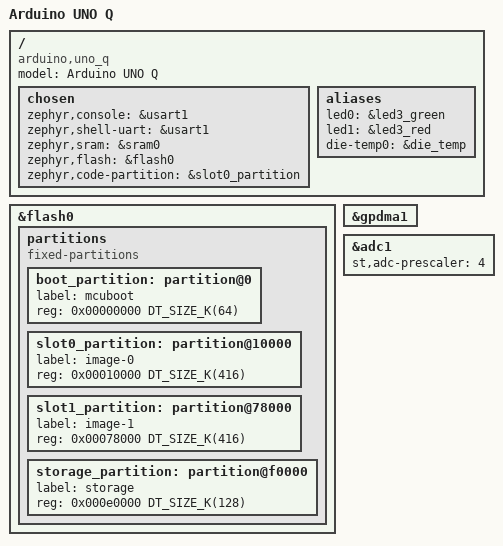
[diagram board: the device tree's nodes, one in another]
/*
 * Copyright (c) 2025 Arduino SA
 *
 * SPDX-License-Identifier: Apache-2.0
 */

/dts-v1/;
#include "arduino_uno_q-common.dtsi"
#include <zephyr/dt-bindings/memory-attr/memory-attr.h>
#include <zephyr/dt-bindings/memory-attr/memory-attr-arm.h>

/ {
	model = "Arduino UNO Q";
	compatible = "arduino,uno_q";

	chosen {
		zephyr,console = &usart1;
		zephyr,shell-uart = &usart1;
		zephyr,sram = &sram0;
		zephyr,flash = &flash0;
		zephyr,code-partition = &slot0_partition;
	};

	aliases {
		led0 = &led3_green;
		led1 = &led3_red;
		die-temp0 = &die_temp;
	};
};

&flash0 {
	partitions {
		compatible = "fixed-partitions";
		#address-cells = <1>;
		#size-cells = <1>;

		/*
		 * Following flash partition is dedicated to the use of stm32u585
		 * with TZEN=0 (so w/o TFM).
		 * Set the partitions with first MB to make use of the whole Bank1
		 */
		boot_partition: partition@0 {
			label = "mcuboot";
			reg = <0x00000000 DT_SIZE_K(64)>;
		};

		slot0_partition: partition@10000 {
			label = "image-0";
			reg = <0x00010000 DT_SIZE_K(416)>;
		};

		slot1_partition: partition@78000 {
			label = "image-1";
			reg = <0x00078000 DT_SIZE_K(416)>;
		};

		storage_partition: partition@f0000 {
			label = "storage";
			reg = <0x000e0000 DT_SIZE_K(128)>;
		};
	};
};

&gpdma1 {
	status = "okay";
};

&adc1 {
	st,adc-prescaler = <4>;
	status = "okay";
};
